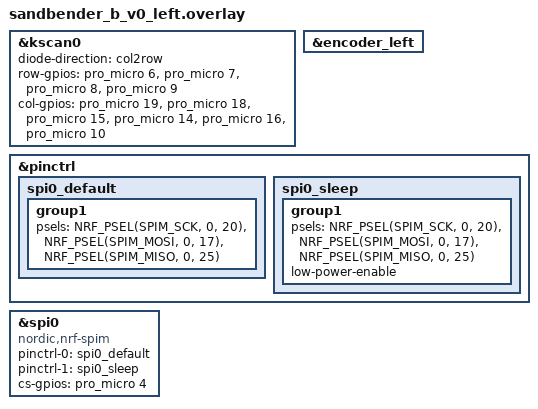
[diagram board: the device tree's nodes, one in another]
#include "sandbender_b_v0.dtsi"

// The ZMK Nice!nano layout, maps pins to align with the green numbers in the
// official pin-out schematic:
//                      https://nicekeyboards.com/docs/nice-nano/pinout-schematic
// I find that the face-down reference is easier to understand when visualizing
// the board:
//                                                                         ╭──────────────╮
//                        ╭──────────┬──────────┬──────────┬──────────╮    |bat        gnd|
//                        │  W       │  E       │  R       │  T       │    |bat          1|
//  ╭──────────┬──────────┼──────────┼──────────┼──────────┼──────────┤    |gnd          0|
//  │  Q       │  A       │  S       │  D       │  F       │  G       │    |reset      gnd|
//  ╰──────────┼──────────┼──────────┼──────────┼──────────┼──────────┤    |3.3v       gnd|
//             │  Z       │  X       │  C       │  V       │  B       │    |21           2|
//             ╰──────────┴──────────┼──────────┼──────────┼──────────┤    |20           3|
//                                   |  del     |  bkspce  |  scroll  |    |19           4|
//                                   ╰──────────┴──────────┴──────────╯ col|18 >|        5|
//                                                                      col|15 >|     >| 6|row
//                                                                      col|14 >|     >| 7|row
//                                                                      col|16 >|     >| 8|row
//                                                                      col|10 >|     >| 9|row
//                                                                         ╰──────────────╯

&kscan0 {
    diode-direction = "col2row"; // col2row = row must have GPIO_ACTIVE_HIGH | GPIO_PULL_DOWN to receive signals

    row-gpios
        = <&pro_micro 6 (GPIO_ACTIVE_HIGH | GPIO_PULL_DOWN)>
        , <&pro_micro 7 (GPIO_ACTIVE_HIGH | GPIO_PULL_DOWN)>
        , <&pro_micro 8 (GPIO_ACTIVE_HIGH | GPIO_PULL_DOWN)>
        , <&pro_micro 9 (GPIO_ACTIVE_HIGH | GPIO_PULL_DOWN)>
    ;

    col-gpios
        = <&pro_micro 19 GPIO_ACTIVE_HIGH>
        , <&pro_micro 18 GPIO_ACTIVE_HIGH>
        , <&pro_micro 15 GPIO_ACTIVE_HIGH>
        , <&pro_micro 14 GPIO_ACTIVE_HIGH>
        , <&pro_micro 16 GPIO_ACTIVE_HIGH>
        , <&pro_micro 10 GPIO_ACTIVE_HIGH>
        ;
};

&encoder_left {
    status = "okay";
};

&pinctrl {
    spi0_default: spi0_default {
        group1 {
            psels = <NRF_PSEL(SPIM_SCK, 0, 20)>,
                <NRF_PSEL(SPIM_MOSI, 0, 17)>,
                <NRF_PSEL(SPIM_MISO, 0, 25)>;
        };
    };
    spi0_sleep: spi0_sleep {
        group1 {
            psels = <NRF_PSEL(SPIM_SCK, 0, 20)>,
                <NRF_PSEL(SPIM_MOSI, 0, 17)>,
                <NRF_PSEL(SPIM_MISO, 0, 25)>;
            low-power-enable;
        };
    };
};

nice_view_spi: &spi0 {
    compatible = "nordic,nrf-spim";
    pinctrl-0 = <&spi0_default>;
    pinctrl-1 = <&spi0_sleep>;
    pinctrl-names = "default", "sleep";
    cs-gpios = <&pro_micro 4 GPIO_ACTIVE_HIGH>;
};
